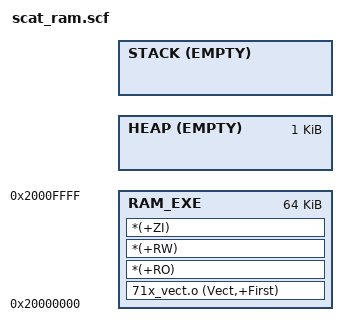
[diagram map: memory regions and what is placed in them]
;******************** (C) COPYRIGHT 2007 STMicroelectronics ********************
;* File Name          : scat_flash.scf
;* Author             : MCD Application Team
;* Version            : V4.0
;* Date               : 10/09/2007
;* Description        : This file provides an example of a scatterloading
;*                      descriptor file that defines one load region in embedded
;*                      RAM and three execution regions.
;*******************************************************************************
; THE PRESENT SOFTWARE WHICH IS FOR GUIDANCE ONLY AIMS AT PROVIDING CUSTOMERS
; WITH CODING INFORMATION REGARDING THEIR PRODUCTS IN ORDER FOR THEM TO SAVE TIME.
; AS A RESULT, STMICROELECTRONICS SHALL NOT BE HELD LIABLE FOR ANY DIRECT,
; INDIRECT OR CONSEQUENTIAL DAMAGES WITH RESPECT TO ANY CLAIMS ARISING FROM THE
; CONTENT OF SUCH SOFTWARE AND/OR THE USE MADE BY CUSTOMERS OF THE CODING
; INFORMATION CONTAINED HEREIN IN CONNECTION WITH THEIR PRODUCTS.
;*******************************************************************************

; The user has to change the RAM length (64/32/16Kbytes) depending on the used 
; STR71x device

RAM_LOAD 0x20000000  0x10000 ; 0x8000/0x4000
{

    RAM_EXE 0x20000000  0x10000 ; 0x8000/ 0x4000
    {
       71x_vect.o (Vect,+First)
         *(+RO)       
         *(+RW)
         *(+ZI)
    }

    ; Heap will grow just above ZI region :
    ; This Symbol is exported to "71x_init.s" file

    HEAP +0 EMPTY 0x400
    {
    }

    ; Stack Base address exported to "71x_init.s" file ( Top of SRAM )

    STACK 0x20004000 EMPTY -0x0
    {
    }
}

;******************* (C) COPYRIGHT 2007 STMicroelectronics *****END OF FILE*****
